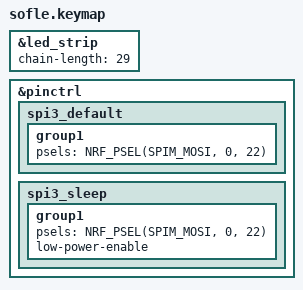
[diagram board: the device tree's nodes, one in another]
/*
 * Copyright (c) 2020 The ZMK Contributors
 *
 * SPDX-License-Identifier: MIT
 */

#include <behaviors.dtsi>
#include <dt-bindings/zmk/keys.h>
#include <dt-bindings/zmk/bt.h>
#include <dt-bindings/zmk/rgb.h>
#include <dt-bindings/zmk/ext_power.h>
#include <dt-bindings/zmk/pointing.h>

#define CONFIG_WIRELESS

&led_strip {
    chain-length = <29>;
};

&pinctrl {
    spi3_default: spi3_default {
        group1 {
            psels = <NRF_PSEL(SPIM_MOSI, 0, 22)>;
        };
    };

    spi3_sleep: spi3_sleep {
        group1 {
            psels = <NRF_PSEL(SPIM_MOSI, 0, 22)>;
            low-power-enable;
        };
    };
};

#include "zmk-helpers/key-labels/sofle.h"
#include "base.keymap"
